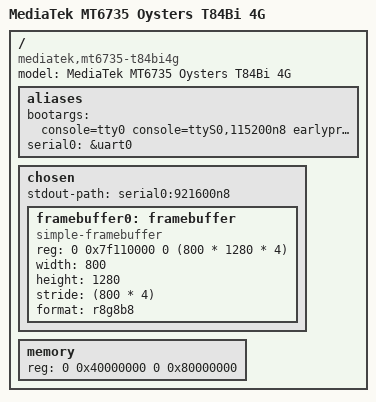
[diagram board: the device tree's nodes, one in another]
// SPDX-License-Identifier: GPL-2.0-or-later
/*
* Author: Maxim Kutnij <gtk3@inbox.ru>
*/

/dts-v1/;
#include "mt6735.dtsi"

/ {
	model = "MediaTek MT6735 Oysters T84Bi 4G";
	compatible = "mediatek,mt6735-t84bi4g", "mediatek,mt6735";

aliases {
		bootargs = "console=tty0 console=ttyS0,115200n8 earlyprintk ignore_loglevel androidboot.hardware=mt6735";
		serial0 = &uart0;
	};

chosen {
		stdout-path = "serial0:921600n8";
		};

	chosen {
		#address-cells = <2>;
		#size-cells = <2>;
		//stdout-path = "serial0:921600n8";
		ranges;
		framebuffer0: framebuffer {
		compatible = "simple-framebuffer";
		reg = <0 0x7f110000 0 (800 * 1280 * 4)>;
		width = <800>;
		height = <1280>;
		stride = <(800 * 4)>;
		format = "r8g8b8";
		status = "okay";
		};
	};


	memory {
		device_type = "memory";
		reg = <0 0x40000000 0 0x80000000>; // Updated by bootloader
	};

};
/*
&uart0 {
	status = "okay";
}; "printk: console [ttyS0] disabled" and reboot

&uart1 {
	status = "okay";
};*/


